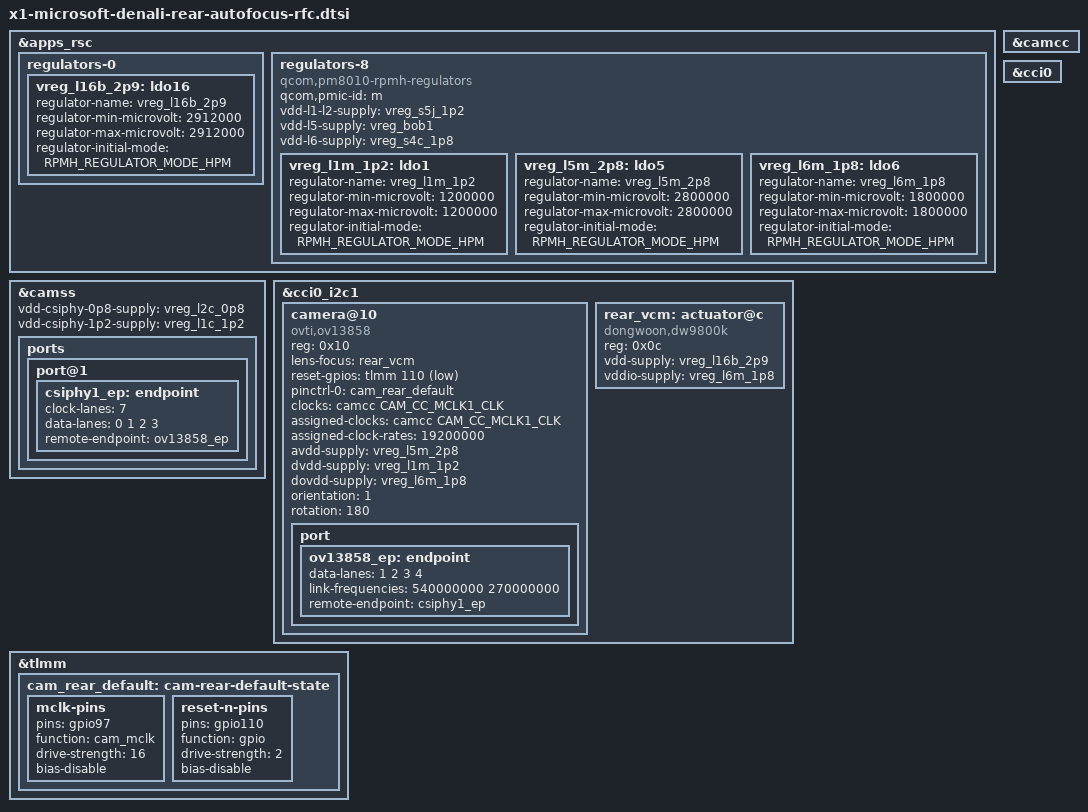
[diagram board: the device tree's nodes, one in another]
/* SPDX-License-Identifier: BSD-3-Clause */
/*
 * SP11 OLED EXPERIMENT ONLY. Not an upstream-ready board DTS.
 * L6M input supply (vreg_s4c_1p8) follows existing Surface Pro 11
 * research; the actual physical parent is NOT independently proven.
 * Do not copy into a shared Denali board description.
 */

&apps_rsc {
	regulators-0 {
		vreg_l16b_2p9: ldo16 {
			regulator-name = "vreg_l16b_2p9";
			/* 2.912 V is the supported PM8550 selector near 2.9 V. */
			regulator-min-microvolt = <2912000>;
			regulator-max-microvolt = <2912000>;
			regulator-initial-mode = <RPMH_REGULATOR_MODE_HPM>;
		};
	};

	regulators-8 {
		compatible = "qcom,pm8010-rpmh-regulators";
		qcom,pmic-id = "m";

		/* PROVISIONAL electrical parent, not schematic-verified. */
		vdd-l1-l2-supply = <&vreg_s5j_1p2>;
		vdd-l5-supply = <&vreg_bob1>;
		vdd-l6-supply = <&vreg_s4c_1p8>;

		vreg_l1m_1p2: ldo1 {
			regulator-name = "vreg_l1m_1p2";
			regulator-min-microvolt = <1200000>;
			regulator-max-microvolt = <1200000>;
			regulator-initial-mode = <RPMH_REGULATOR_MODE_HPM>;
		};

		vreg_l5m_2p8: ldo5 {
			regulator-name = "vreg_l5m_2p8";
			regulator-min-microvolt = <2800000>;
			regulator-max-microvolt = <2800000>;
			regulator-initial-mode = <RPMH_REGULATOR_MODE_HPM>;
		};

		vreg_l6m_1p8: ldo6 {
			regulator-name = "vreg_l6m_1p8";
			regulator-min-microvolt = <1800000>;
			regulator-max-microvolt = <1800000>;
			regulator-initial-mode = <RPMH_REGULATOR_MODE_HPM>;
		};
	};
};

&camcc {
	status = "okay";
};

&camss {
	vdd-csiphy-0p8-supply = <&vreg_l2c_0p8>;
	vdd-csiphy-1p2-supply = <&vreg_l1c_1p2>;
	status = "okay";

	ports {
		port@1 {
			csiphy1_ep: endpoint {
				clock-lanes = <7>;
				data-lanes = <0 1 2 3>;
				remote-endpoint = <&ov13858_ep>;
			};
		};
	};
};

&cci0 {
	status = "okay";
};

&cci0_i2c1 {
	camera@10 {
		compatible = "ovti,ov13858";
		reg = <0x10>;
		lens-focus = <&rear_vcm>;
		reset-gpios = <&tlmm 110 GPIO_ACTIVE_LOW>;
		pinctrl-0 = <&cam_rear_default>;
		pinctrl-names = "default";

		clocks = <&camcc CAM_CC_MCLK1_CLK>;
		assigned-clocks = <&camcc CAM_CC_MCLK1_CLK>;
		assigned-clock-rates = <19200000>;

		avdd-supply = <&vreg_l5m_2p8>;
		dvdd-supply = <&vreg_l1m_1p2>;
		dovdd-supply = <&vreg_l6m_1p8>;

		orientation = <1>;
		rotation = <180>;

		port {
			ov13858_ep: endpoint {
				data-lanes = <1 2 3 4>;
				link-frequencies = /bits/ 64 <540000000 270000000>;
				remote-endpoint = <&csiphy1_ep>;
			};
		};
	};

	rear_vcm: actuator@c {
		compatible = "dongwoon,dw9800k";
		reg = <0x0c>;
		vdd-supply = <&vreg_l16b_2p9>;
		vddio-supply = <&vreg_l6m_1p8>;
	};
};

&tlmm {
	cam_rear_default: cam-rear-default-state {
		mclk-pins {
			pins = "gpio97";
			function = "cam_mclk";
			drive-strength = <16>;
			bias-disable;
		};

		reset-n-pins {
			pins = "gpio110";
			function = "gpio";
			drive-strength = <2>;
			bias-disable;
		};
	};
};
